# LIS331EB register map
Vendor: STMicroelectronics; Series: LIS331EB; File version: 1.0
CPU: CM0 r0p0, little endian, no MPU, no FPU, 5 interrupt priority bits
Registers are 32-bit, read-write, reset 0x0 unless marked. A register's access mark holds for its fields unless they carry their own. Offsets are from the block's base; [hi:lo] are bit positions.

## I2CM — I2C Master
Base 0xA4000000
Same registers: I2CS 0xA5000000
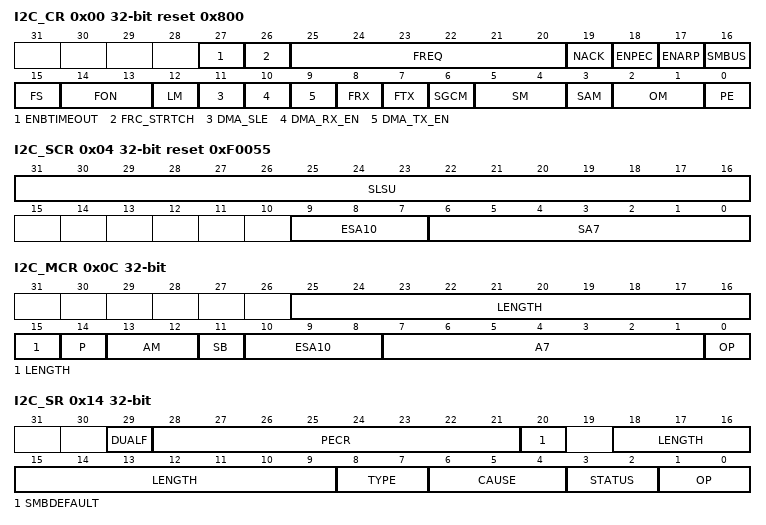
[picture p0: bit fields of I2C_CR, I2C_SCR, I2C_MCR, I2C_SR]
0x00 I2C_CR reset 0x800 — I2C Control register
  [27] ENBTIMEOUT — Timeout enable (SMBUS mode)
  [26] FRC_STRTCH — Clock stretching force (SMBUS mode)
  [25:20] FREQ — Internal clock frequency (SMBUS)
  [19] NACK — Not-Acknowledge enable (SMBUS)
  [18] ENPEC — PEC enable (SMBUS)
  [17] ENARP — ARP enable (SMBUS)
  [16] SMBUS — SMBus mode
    0=I2C_MODE; 1=SMBUS_MODE
  [15] FS — Force stop enable bit. When set to 1b, the STOP condition is generated
  [14:13] FON — Filtering on
    0=None (No digital filters are inserted); 1=1CK_SPIKES (Digital filters (filter 1 ck wide spikes) are inserted); 2=2CK_SPIKES (Digital filters (filter 2 ck wide spikes) are inserted); 3=4CK_SPIKES (Digital filters (filter 4 ck wide spikes) are inserted)
  [12] LM — LM sets the loopback operating mode for the I2C controller
  [11] DMA_SLE — DMA synchronization logic enable
  [10] DMA_RX_EN — DMA_RX_EN enables the DMA Rx interface to generate burst/single requests for a single DMA descriptor until a master read or write-to-slave operation has been execute
  [9] DMA_TX_EN — DMA_TX_EN enables the DMA Tx interface to generate burst/single requests for a single DMA descriptor until a master write or read-from-slave operation has been executed
  [8] FRX write-1-sets — FRX flushes the receive circuitry (FIFO, fsm)
  [7] FTX write-1-sets — FTX flushes the transmit circuitry (FIFO, fsm)
  [6] SGCM — Slave general call mode. SGCM defines the operating mode of the slave controller when a general call (with B bit set to 0) is received.
    0=Transparent mode, the slave receiver recognizes the general call ut any action is taken by software after the decoding of the message included in the Rx FIFO; 1=Direct mode, the slave receiver recognizes the general call and executes directly (without software intervention) the related actions. Only the status code word is stored in the I2C_SR register for notification to the application
  [5:4] SM — Speed mode. SM defines the speed mode related to the serial bit rate
    0=Standard mode (up to 100 K/s); 1=Fast mode (up to 400 K/s); 2=HighSpeed_Mode (High-speed (up to 3.4 M/s)); 3=Fast-mode plus (up to 1 M/s)
  [3] SAM — Slave addressing mode. SAM defines the slave addressing mode when the peripheral works in slave or master/slave mode. The received address is compared with the content of the register I2C_SCR
    0=7-bit addressing mode; 1=10-bit addressing mode
  [2:1] OM — Operating mode
    0=Slave (The peripheral can only respond (transmit/receive) when addresses by a master device); 1=Master (The peripheral works in a multi-master system where itself cannot by addresses by another master device. It can only initiate a new transfer as master device); 2=Master_Slave (The peripheral works in a multi-master system where itself can by addresses by another master device, besides to initiate a transfer as master device)
  [0] PE — Peripheral enable. PE enables the peripheral to work in the operating mode set by the I2C_CR:OM register field
0x04 I2C_SCR reset 0xF0055 — I2C Slave Control register
  [31:16] SLSU — Slave data setup time. SLSU defines the data setup time after SCL clock stretching in terms of i2c_clk cycles
  [9:7] ESA10 — Extended slave address 10-bit. ESA10 includes the extension (MSB bits) to the SA7 register field in case of slave addressing mode set to 10-bit
  [6:0] SA7 — Slave address 7-bit. SA7 includes the slave address 7-bit or the LSB bits of the slave address 10-bit
0x08 I2C_HSMCR — I2C high-speed master code register
  [2:0] MC — Master code. MC defines the last 3 bits of the master code
0x0C I2C_MCR — I2C master control register
  [25:15] LENGTH — Transaction length
  [14] P — Stop Condition
  [13:12] AM — Address Type
    0=General_Call (The transaction is initiated by a general call command); 1=7bit_Address (The transaction is initiated by the 7-bit address included in the A7 field); 2=10bit_Address (The transaction is initiated by the 10-bit address included in the EA10 and A7 fields)
  [11] SB — Extended address
  [10:8] ESA10 — Extended address. Includes the extension (MSB bits) of the field A7 used to initiate the current transaction
  [7:1] A7 — Address. Includes the 7-bit address or the LSB bits of the10-bit address used to initiate the current transaction
  [0] OP — Operation
    0=Master_Write (Indicates a master write operation); 1=Master_Read (Indicates a master read operation)
0x10 I2C_TFR — I2C transmit FIFO register
  [7:0] TDATA — Transmission Data. TDATA contains the payload related to a master write or read-from-slave operation to be written in the Tx FIFO
0x14 I2C_SR ro — I2C status register
  [29] DUALF — Dual flag (Slave mode)
  [28:21] PECR — Packet error checking register
  [20] SMBDEFAULT — SMBus device default address (Slave mode)
  [18:9] LENGTH — Transfer length
  [8:7] TYPE — Receive type
    0=FRAME (The slave has received a normal frame); 1=GCALL (The slave has received a general call); 2=HW_GCALL (The slave has received a hardware general call)
  [6:4] CAUSE — Abort Cause
    0=NACK_ADDR (The master receives a not-acknowledge after the transmission of the address); 1=NACK_DATA (The master receives a not-acknowledge during the data phase of a MW operation); 2=ACK_MCODE (The master receives an acknowledge after the transmission of the master code in Hs mode); 3=ARB_LOST (The master loses the arbitration during a MW or MR operation); 4=BERR_START (Slave restarts, a START Condition occurs while the byte transfer is not terminated); 5=BERR_STOP (Slave reset, a STOP Condition while the byte transfer is not terminated); 6=OVFL (The slave receives a frame related to the WTS operation longer than the maximum size = 2047 bytes)
  [3:2] STATUS — Controller status
    0=NOP (No operation is in progress); 1=ON_GOING (An operation is ongoing); 2=OK (The operation (OP field) has been completed successfully); 3=ABORT (The operation (OP field) has been aborted due to the occurrence of the event descried in the CAUSE field)
  [1:0] OP — Operation
    0=MW (Master write operation); 1=MR (Master read operation); 2=WTS (Write to slave operation); 3=RFS (Read from slave operation)
0x18 I2C_RFR — I2C receive FIFO register
  [7:0] RDATA — Receive Data
0x1C I2C_TFTR — I2C transmit FIFO threshold register
  [9:0] THRESHOLD_TX
0x20 I2C_RFTR — I2C receive FIFO threshold register
  [9:0] THRESHOLD_RX
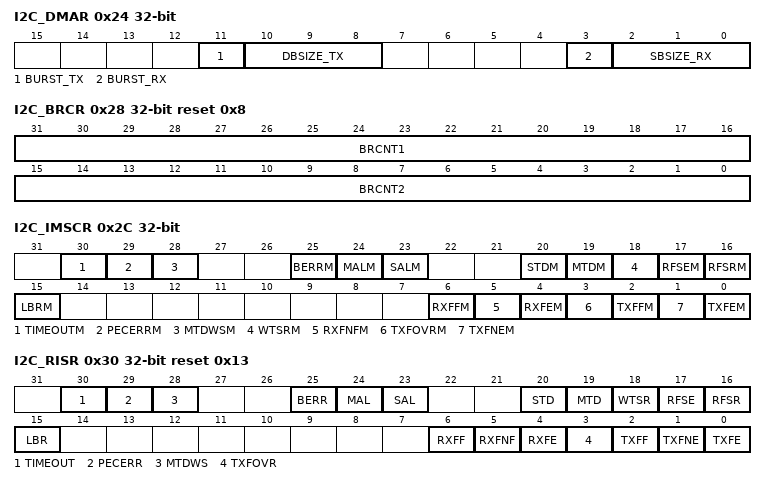
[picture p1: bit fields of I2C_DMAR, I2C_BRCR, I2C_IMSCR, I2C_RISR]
0x24 I2C_DMAR — I2C DMA register
  [11] BURST_TX
  [10:8] DBSIZE_TX — Destination Burst Size Tx
  [3] BURST_RX — Burst RxBURST_RX defines the type of DMA requests generated by the DMA Rx interface
  [2:0] SBSIZE_RX — Source Burst Size Rx
0x28 I2C_BRCR reset 0x8 — I2C Baud-rate counter register
  [31:16] BRCNT1 — Baud rate counter 1
  [15:0] BRCNT2 — Baud rate counter 2
0x2C I2C_IMSCR — I2C interrupt mask set/clear register
  [30] TIMEOUTM — Timeout or Tlow error mask
  [29] PECERRM — PEC Error in reception mask
  [28] MTDWSM — Master Transaction done without stop mask
  [25] BERRM — Bus Error mask
  [24] MALM — Master Arbitration lost mask
  [23] SALM — Slave Arbitration lost mask
  [20] STDM — Slave Transaction done mask
  [19] MTDM — Master Transaction done mask
  [18] WTSRM — Write-to-Slave request mask
  [17] RFSEM — Read-from-Slave empty mask
  [16] RFSRM — Read-from-Slave request mask
  [15] LBRM — Length number of bytes received mask
  [6] RXFFM — Rx FIFO full mask
  [5] RXFNFM — Rx FIFO nearly full mask
  [4] RXFEM — Rx FIFO empty mask
  [3] TXFOVRM — Tx FIFO overrun mask
  [2] TXFFM — Tx FIFO full mask
  [1] TXFNEM — Tx FIFO nearly empty mask
  [0] TXFEM — Tx FIFO empty mask
0x30 I2C_RISR ro reset 0x13 — I2C raw interrupt status register
  [30] TIMEOUT — Timeout or Tlow error
  [29] PECERR — PEC Error in reception
  [28] MTDWS — Master Transaction done without stop
  [25] BERR — Bus Error
  [24] MAL — Master Arbitration lost
  [23] SAL — Slave Arbitration lost
  [20] STD — Slave Transaction done
  [19] MTD — Master Transaction done
  [18] WTSR — Write-to-Slave request
  [17] RFSE — Read-from-Slave empty
  [16] RFSR — Read-from-Slave request
  [15] LBR — Length number of bytes received
  [6] RXFF — Rx FIFO full
  [5] RXFNF — Rx FIFO nearly full
  [4] RXFE — Rx FIFO empty
  [3] TXFOVR — Tx FIFO overrun
  [2] TXFF — Tx FIFO full
  [1] TXFNE — Tx FIFO nearly empty
  [0] TXFE — Tx FIFO empty
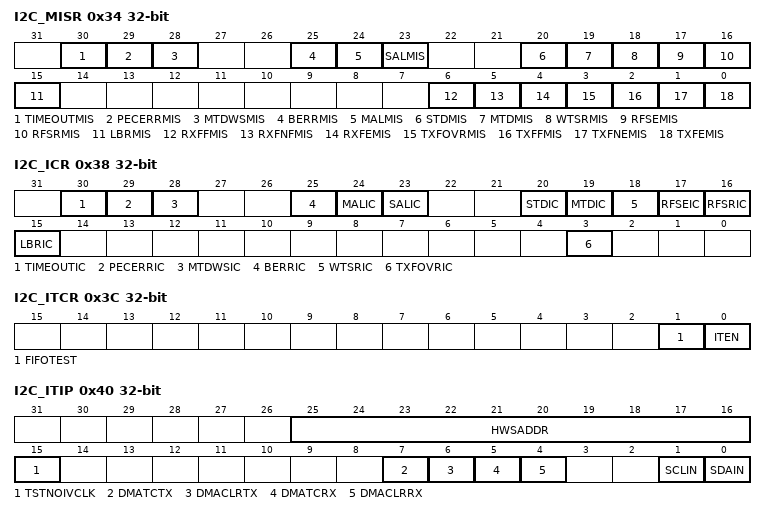
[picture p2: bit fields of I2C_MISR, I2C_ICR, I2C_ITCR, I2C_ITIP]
0x34 I2C_MISR ro — I2C masked interrupt status register
  [30] TIMEOUTMIS — Timeout or Tlow error masked interrupt status
  [29] PECERRMIS — PEC Error in reception masked interrupt status
  [28] MTDWSMIS — Master Transaction done without stop masked interrupt status
  [25] BERRMIS — Bus Error masked interrupt status
  [24] MALMIS — Master Arbitration lost masked interrupt status
  [23] SALMIS — Slave Arbitration lost masked interrupt status
  [20] STDMIS — Slave Transaction done masked interrupt status
  [19] MTDMIS — Master Transaction done masked interrupt status
  [18] WTSRMIS — Write-to-Slave request masked interrupt status
  [17] RFSEMIS — Read-from-Slave empty masked interrupt status
  [16] RFSRMIS — Read-from-Slave request masked interrupt status
  [15] LBRMIS — Length number of bytes received masked interrupt status
  [6] RXFFMIS — Rx FIFO full masked interrupt status
  [5] RXFNFMIS — Rx FIFO nearly full masked interrupt status
  [4] RXFEMIS — Rx FIFO empty masked interrupt status
  [3] TXFOVRMIS — Tx FIFO overrun masked interrupt status
  [2] TXFFMIS — Tx FIFO full masked interrupt status
  [1] TXFNEMIS — Tx FIFO nearly empty masked interrupt status
  [0] TXFEMIS — Tx FIFO empty masked interrupt status
0x38 I2C_ICR write-1-clears — I2C interrupt clear register
  [30] TIMEOUTIC — Timeout or Tlow error interrupt clear
  [29] PECERRIC — PEC Error in reception interrupt clear
  [28] MTDWSIC — Master Transaction done without stop interrupt clear
  [25] BERRIC — Bus Error interrupt clear
  [24] MALIC — Master Arbitration lost interrupt clear
  [23] SALIC — Slave Arbitration lost interrupt clear
  [20] STDIC — Slave Transaction done interrupt clear
  [19] MTDIC — Master Transaction done interrupt clear
  [18] WTSRIC — Write-to-Slave request interrupt clear
  [17] RFSEIC — Read-from-Slave empty interrupt clear
  [16] RFSRIC — Read-from-Slave request interrupt clear
  [15] LBRIC — Length number of bytes received interrupt clear
  [3] TXFOVRIC — Tx FIFO overrun interrupt clear
0x3C I2C_ITCR — I2C interaction test control register
  [1] FIFOTEST
  [0] ITEN — Integration test enable
0x40 I2C_ITIP — I2C interaction test input register
  [25:16] HWSADDR — Hardware slave address input value
  [15] TSTNOIVCLK — Test edge clock input value
  [7] DMATCTX — Transmit DMA terminal count input value
  [6] DMACLRTX — Transmit DMA Clear input value
  [5] DMATCRX — Receive DMA terminal count input value
  [4] DMACLRRX — Receive DMA Clear input value
  [1] SCLIN — Clock input value
  [0] SDAIN — I2C data input value
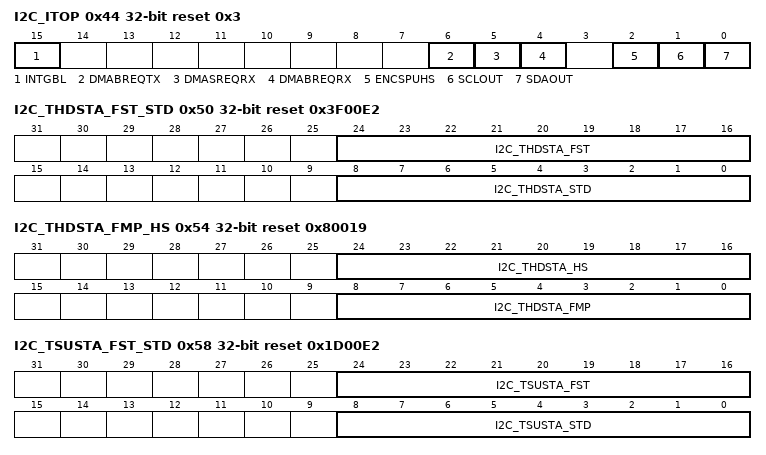
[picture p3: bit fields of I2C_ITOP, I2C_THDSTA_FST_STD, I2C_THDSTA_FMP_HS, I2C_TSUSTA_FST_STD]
0x44 I2C_ITOP reset 0x3 — I2C interaction test output register
  [15] INTGBL — Global Interrupt output value
  [6] DMABREQTX — Transmit burst request output value
  [5] DMASREQRX — Receive single request output value
  [4] DMABREQRX — Receive burst request output value
  [2] ENCSPUHS — Enable current source output value
  [1] SCLOUT — Clock output value
  [0] SDAOUT — I2C data output value
0x48 I2C_TDR — I2C test data register
  [31:0] TESTDATA — FIFO test data
0x4C I2C_THDDAT reset 0x14 — I2C hold time data
  [8:0] I2C_THDDAT — Hold time data value
0x50 I2C_THDSTA_FST_STD reset 0x3F00E2 — I2C hold time start condition F/S
  [24:16] I2C_THDSTA_FST — Hold time start condition value for fast mode
  [8:0] I2C_THDSTA_STD — Hold time start condition value for standard mode
0x54 I2C_THDSTA_FMP_HS reset 0x80019 — I2C hold time start condition FMP/HS
  [24:16] I2C_THDSTA_HS — Hold time start condition value for hs-mode
  [8:0] I2C_THDSTA_FMP — Hold time start condition value for fmp mode
0x58 I2C_TSUSTA_FST_STD reset 0x1D00E2 — I2C setup time start condition F/S
  [24:16] I2C_TSUSTA_FST — Setup time start condition value for fast mode
  [8:0] I2C_TSUSTA_STD — Setup time start condition value for standard mode
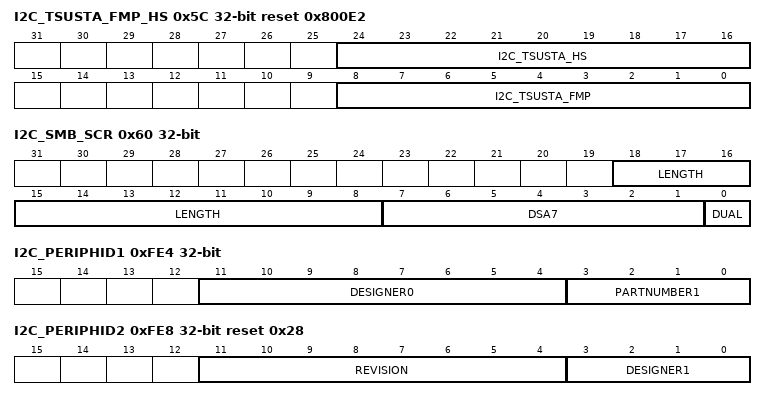
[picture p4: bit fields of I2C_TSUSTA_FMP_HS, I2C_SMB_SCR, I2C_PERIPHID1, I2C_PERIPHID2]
0x5C I2C_TSUSTA_FMP_HS reset 0x800E2 — I2C setup time start condition FMP/HS
  [24:16] I2C_TSUSTA_HS — Setup time start condition value for fast mode
  [8:0] I2C_TSUSTA_FMP — Setup time start condition value for standard mode
0x60 I2C_SMB_SCR — SMBUS slave control register
  [18:8] LENGTH — The I2C_SMB_SCR registers Transaction length
  [7:1] DSA7 — Slave address in dual addressing mode
  [0] DUAL — Dual addressing mode enable
0xFE0 I2C_PERIPHID0 ro reset 0x24 — I2C peripheral identification register 0
  [7:0] PARTNUMBER0 — These bits read back as 0x024
0xFE4 I2C_PERIPHID1 ro (reset mask 0xFF) — I2C peripheral identification register 1
  [11:4] DESIGNER0 — These bits read back as 0x00
  [3:0] PARTNUMBER1 — These bits read back as 0x00
0xFE8 I2C_PERIPHID2 ro reset 0x28 (reset mask 0xFF) — I2C peripheral identification register 2
  [11:4] REVISION — These bits read back as 0x2
  [3:0] DESIGNER1 — These bits read back as 0x08
0xFEC I2C_PERIPHID3 ro — I2C peripheral identification register 3
  [7:0] CONFIGURATION — These bits read back as 0x00
0xFF0 I2C_PCELLID0 ro reset 0xD — I2C PCell Identification register 0
  [7:0] I2CPCELLID0 — These bits read back as 0x0D
0xFF4 I2C_PCELLID1 ro reset 0xF0 — I2C PCell Identification register 1
  [7:0] I2CPCELLID1 — These bits read back as 0xF0
0xFF8 I2C_PCELLID2 ro reset 0x5 — I2C PCell Identification register 2
  [7:0] I2CPCELLID2 — These bits read back as 0x05
0xFFC I2C_PCELLID3 ro reset 0xB1 — I2C PCell Identification register 3
  [7:0] I2CPCELLID3 — These bits read back as 0xB1
